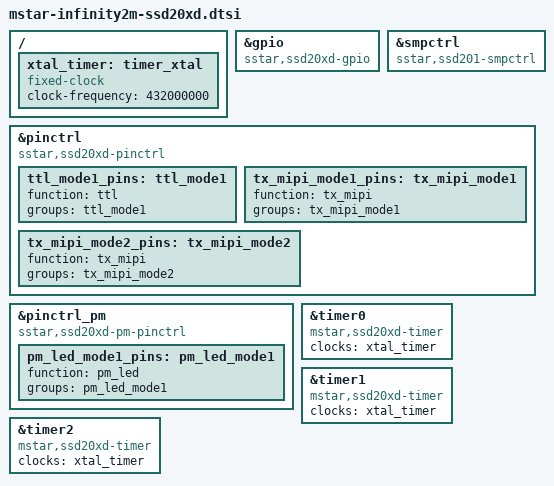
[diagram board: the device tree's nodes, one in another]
// SPDX-License-Identifier: GPL-2.0-or-later
/*
 * Copyright (c) 2020 thingy.jp.
 * Author: Daniel Palmer <daniel@thingy.jp>
 */

#include "mstar-infinity2m.dtsi"

/ {
	xtal_timer: timer_xtal {
		#clock-cells = <0>;
		compatible = "fixed-clock";
		clock-frequency = <432000000>;
	};
};

&gpio {
	compatible = "sstar,ssd20xd-gpio";
	status = "okay";
};

&smpctrl {
	compatible = "sstar,ssd201-smpctrl", "mstar,smpctrl";
	status = "okay";
};

&pinctrl {
	compatible = "sstar,ssd20xd-pinctrl";
	ttl_mode1_pins: ttl_mode1 {
		function = "ttl";
		groups = "ttl_mode1";
	};
	tx_mipi_mode1_pins: tx_mipi_mode1 {
		function = "tx_mipi";
		groups = "tx_mipi_mode1";
	};
	tx_mipi_mode2_pins: tx_mipi_mode2 {
		function = "tx_mipi";
		groups = "tx_mipi_mode2";
	};
};

&pinctrl_pm {
	compatible = "sstar,ssd20xd-pm-pinctrl";
	pm_led_mode1_pins: pm_led_mode1 {
		function = "pm_led";
		groups = "pm_led_mode1";
	};
};

&timer0 {
	compatible = "mstar,ssd20xd-timer";
	clocks = <&xtal_timer>;
};

&timer1 {
	compatible = "mstar,ssd20xd-timer";
	clocks = <&xtal_timer>;
};

&timer2 {
	compatible = "mstar,ssd20xd-timer";
	clocks = <&xtal_timer>;
};
